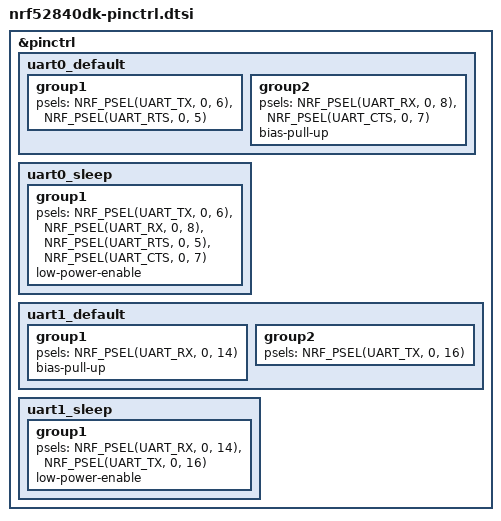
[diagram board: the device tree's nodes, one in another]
&pinctrl {
	uart0_default: uart0_default {
		group1 {
			psels =	<NRF_PSEL(UART_TX, 0, 6)>,
					<NRF_PSEL(UART_RTS, 0, 5)>;
		};
		group2 {
			psels =	<NRF_PSEL(UART_RX, 0, 8)>,
					<NRF_PSEL(UART_CTS, 0, 7)>;
			bias-pull-up;
		};
	};
	uart0_sleep: uart0_sleep {
		group1 {
			psels =	<NRF_PSEL(UART_TX, 0, 6)>,
					<NRF_PSEL(UART_RX, 0, 8)>,
					<NRF_PSEL(UART_RTS, 0, 5)>,
					<NRF_PSEL(UART_CTS, 0, 7)>;
			low-power-enable;
		};
	};
	uart1_default: uart1_default {
		group1 {
			psels = <NRF_PSEL(UART_RX, 0, 14)>;
			bias-pull-up;
		};
		group2 {
			psels = <NRF_PSEL(UART_TX, 0, 16)>;
		};
	};
	uart1_sleep: uart1_sleep {
	   group1 {
			psels = <NRF_PSEL(UART_RX, 0, 14)>,
		  			<NRF_PSEL(UART_TX, 0, 16)>;
		  low-power-enable;
		};
	};
};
